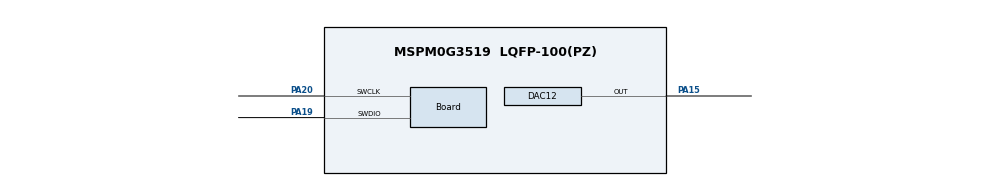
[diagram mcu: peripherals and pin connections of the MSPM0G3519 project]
//@cliArgs --device "MSPM0G351X" --package "LQFP-100(PZ)" --part "Default"
//@v2CliArgs --device "MSPM0G3519" --package "LQFP-100(PZ)"
// @cliArgs --board /ti/boards/LP_MSPM0G3519 --rtos nortos

/**
 * Import the modules used in this configuration.
 */
const ADC12   = scripting.addModule("/ti/driverlib/ADC12", {}, false);
const ADC121  = ADC12.addInstance();
const DAC12   = scripting.addModule("/ti/driverlib/DAC12");
const MATHACL = scripting.addModule("/ti/driverlib/MATHACL");
const SYSCTL  = scripting.addModule("/ti/driverlib/SYSCTL");

/**
 * Write custom configuration values to the imported modules.
 */
ADC121.$name                      = "ADC12_0";
ADC121.sampClkSrc                 = "DL_ADC12_CLOCK_ULPCLK";
ADC121.sampClkDiv                 = "DL_ADC12_CLOCK_DIVIDE_8";
ADC121.adcMem0chansel             = "DL_ADC12_INPUT_CHAN_2";
ADC121.sampleTime0                = "48.5 us";
ADC121.enabledInterrupts          = ["DL_ADC12_INTERRUPT_MEM0_RESULT_LOADED"];
ADC121.repeatMode                 = true;
ADC121.peripheral.$assign         = "ADC0";
ADC121.peripheral.adcPin2.$assign = "PA25";

const Board                       = scripting.addModule("/ti/driverlib/Board", {}, false);
Board.peripheral.$assign          = "DEBUGSS";
Board.peripheral.swclkPin.$assign = "PA20";
Board.peripheral.swdioPin.$assign = "PA19";

DAC12.dacOutputPinEn            = true;
DAC12.dacAmplifier              = "ON";
DAC12.peripheral.$assign        = "DAC0";
DAC12.peripheral.OutPin.$assign = "PA15";

SYSCTL.MFCLKEn               = true;
SYSCTL.MFPCLKEn              = true;
SYSCTL.forceDefaultClkConfig = true;
SYSCTL.peripheral.$assign    = "SYSCTL";

const ProjectConfig              = scripting.addModule("/ti/project_config/ProjectConfig", {}, false);
ProjectConfig.migrationCondition = true;
